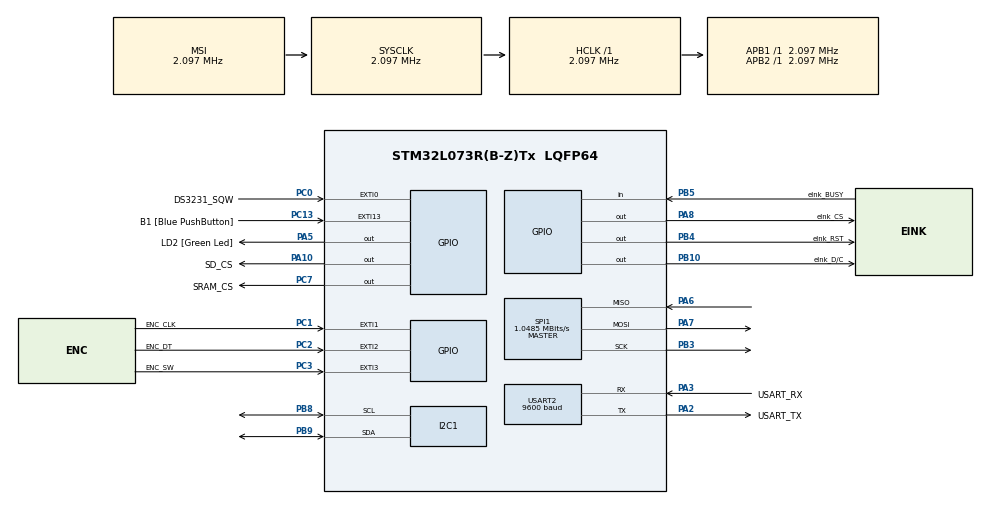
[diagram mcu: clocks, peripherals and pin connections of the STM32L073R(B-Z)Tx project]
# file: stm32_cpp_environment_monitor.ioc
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Dma.Request0=SPI1_TX
Dma.Request1=SPI1_RX
Dma.SPI1_RX.1.Direction=DMA_PERIPH_TO_MEMORY
Dma.SPI1_RX.1.Instance=DMA1_Channel2
Dma.SPI1_RX.1.MemDataAlignment=DMA_MDATAALIGN_BYTE
Dma.SPI1_RX.1.MemInc=DMA_MINC_ENABLE
Dma.SPI1_RX.1.Mode=DMA_NORMAL
Dma.SPI1_RX.1.PeriphDataAlignment=DMA_PDATAALIGN_BYTE
Dma.SPI1_RX.1.PeriphInc=DMA_PINC_DISABLE
Dma.SPI1_RX.1.Priority=DMA_PRIORITY_HIGH
Dma.SPI1_TX.0.Direction=DMA_MEMORY_TO_PERIPH
Dma.SPI1_TX.0.Instance=DMA1_Channel3
Dma.SPI1_TX.0.MemDataAlignment=DMA_MDATAALIGN_BYTE
Dma.SPI1_TX.0.MemInc=DMA_MINC_ENABLE
Dma.SPI1_TX.0.Mode=DMA_NORMAL
Dma.SPI1_TX.0.PeriphDataAlignment=DMA_PDATAALIGN_BYTE
Dma.SPI1_TX.0.PeriphInc=DMA_PINC_DISABLE
Dma.SPI1_TX.0.Priority=DMA_PRIORITY_HIGH
FATFS._USE_MKFS=0
I2C1.Timing=0x00503D58
Mcu.Family=STM32L0
Mcu.Name=STM32L073R(B-Z)Tx
Mcu.Package=LQFP64
NVIC.DMA1_Channel2_3_IRQn=true\:0\:0\:false\:false\:true\:false\:true\:true
NVIC.EXTI0_1_IRQn=true\:0\:0\:false\:false\:true\:true\:true\:true
NVIC.EXTI2_3_IRQn=true\:0\:0\:false\:false\:true\:true\:true\:true
PA10.GPIO_Label=SD_CS
PA10.PinState=GPIO_PIN_SET
PA10.Signal=GPIO_Output
PA13.GPIO_Label=TMS
PA13.Mode=Serial_Wire
PA13.Signal=SYS_SWDIO
PA14.GPIO_Label=TCK
PA14.Mode=Serial_Wire
PA14.Signal=SYS_SWCLK
PA2.GPIO_Label=USART_TX
PA2.Mode=Asynchronous
PA2.Signal=USART2_TX
PA3.GPIO_Label=USART_RX
PA3.Mode=Asynchronous
PA3.Signal=USART2_RX
PA5.GPIO_Label=LD2 [Green Led]
PA5.Signal=GPIO_Output
PA6.Mode=Full_Duplex_Master
PA6.Signal=SPI1_MISO
PA7.Mode=Full_Duplex_Master
PA7.Signal=SPI1_MOSI
PA8.GPIO_Label=eInk_CS
PA8.PinState=GPIO_PIN_SET
PA8.Signal=GPIO_Output
PB10.GPIO_Label=eInk_D/C
PB10.Signal=GPIO_Output
PB3.Mode=Full_Duplex_Master
PB3.Signal=SPI1_SCK
PB4.GPIO_Label=eInk_RST
PB4.PinState=GPIO_PIN_SET
PB4.Signal=GPIO_Output
PB5.GPIO_Label=eInk_BUSY
PB5.Signal=GPIO_Input
PB8.GPIO_FM8=I2C_FASTMODEPLUS_PB8
PB8.Mode=I2C
PB8.Signal=I2C1_SCL
PB9.GPIO_FM9=I2C_FASTMODEPLUS_PB9
PB9.Mode=I2C
PB9.Signal=I2C1_SDA
PC0.GPIO_Label=DS3231_SQW
PC0.GPIO_ModeDefaultEXTI=GPIO_MODE_IT_FALLING
PC0.GPIO_PuPd=GPIO_PULLUP
PC0.Signal=GPXTI0
PC1.GPIO_Label=ENC_CLK
PC1.GPIO_ModeDefaultEXTI=GPIO_MODE_IT_RISING_FALLING
PC1.GPIO_PuPd=GPIO_PULLUP
PC1.Signal=GPXTI1
PC13.GPIO_Label=B1 [Blue PushButton]
PC13.GPIO_ModeDefaultEXTI=GPIO_MODE_IT_FALLING
PC13.Signal=GPXTI13
PC14-OSC32_IN.Mode=LSE-External-Oscillator
PC14-OSC32_IN.Signal=RCC_OSC32_IN
PC15-OSC32_OUT.Mode=LSE-External-Oscillator
PC15-OSC32_OUT.Signal=RCC_OSC32_OUT
PC2.GPIO_Label=ENC_DT
PC2.GPIO_ModeDefaultEXTI=GPIO_MODE_IT_RISING_FALLING
PC2.GPIO_PuPd=GPIO_PULLUP
PC2.Signal=GPXTI2
PC3.GPIO_Label=ENC_SW
PC3.GPIO_ModeDefaultEXTI=GPIO_MODE_IT_FALLING
PC3.GPIO_PuPd=GPIO_PULLUP
PC3.Signal=GPXTI3
PC7.GPIO_Label=SRAM_CS
PC7.PinState=GPIO_PIN_SET
PC7.Signal=GPIO_Output
PH0-OSC_IN.GPIO_Label=MCO
PH0-OSC_IN.Signal=RCC_OSC_IN
ProjectManager.HeapSize=0x200
ProjectManager.StackSize=0x400
ProjectManager.TargetToolchain=CMake
RCC.AHBFreq_Value=2097000
RCC.APB1Freq_Value=2097000
RCC.APB1TimFreq_Value=2097000
RCC.APB2Freq_Value=2097000
RCC.APB2TimFreq_Value=2097000
RCC.HSE_VALUE=8000000
RCC.HSI16_VALUE=16000000
RCC.HSI48_VALUE=48000000
RCC.HSI_VALUE=16000000
RCC.I2c1ClockSelection=RCC_I2C1CLKSOURCE_HSI
RCC.MSI_VALUE=2097000
RCC.PWR_Regulator_Voltage_Scale=PWR_REGULATOR_VOLTAGE_SCALE3
RCC.SYSCLKFreq_VALUE=2097000
RCC.VCOOutputFreq_Value=48000000
SPI1.CalculateBaudRate=1.0485 MBits/s
SPI1.Direction=SPI_DIRECTION_2LINES
SPI1.Mode=SPI_MODE_MASTER
SPI1.VirtualType=VM_MASTER
USART2.BaudRate=9600
USART2.VirtualMode-Asynchronous=VM_ASYNC
VP_FATFS_VS_Generic.Mode=User_defined
board=NUCLEO-L073RZ

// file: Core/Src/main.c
/* USER CODE BEGIN Header */
/**
  ******************************************************************************
  * @file           : main.c
  * @brief          : Main program body
  ******************************************************************************
  * @attention
  *
  * Copyright (c) 2026 STMicroelectronics.
  * All rights reserved.
  *
  * This software is licensed under terms that can be found in the LICENSE file
  * in the root directory of this software component.
  * If no LICENSE file comes with this software, it is provided AS-IS.
  *
  ******************************************************************************
  */
/* USER CODE END Header */
#include "main.h"
#include "fatfs.h"

/* USER CODE BEGIN Includes */
#include "app.h"
/* USER CODE END Includes */

UART_HandleTypeDef huart2;

void SystemClock_Config(void);
static void MX_GPIO_Init(void);
static void MX_DMA_Init(void);
static void MX_SPI1_Init(void);
static void MX_USART2_UART_Init(void);
static void MX_I2C1_Init(void);

int main(void)
{

  /* MCU Configuration--------------------------------------------------------*/

  /* Reset of all peripherals, Initializes the Flash interface and the Systick. */
  HAL_Init();

  /* Configure the system clock */
  SystemClock_Config();

  /* Initialize all configured peripherals */
  MX_GPIO_Init();
  MX_DMA_Init();
  MX_SPI1_Init();
  MX_USART2_UART_Init();
  MX_I2C1_Init();
  MX_FATFS_Init();
  /* USER CODE BEGIN 2 */
  AppMain();
  /* USER CODE END 2 */

  /* Infinite loop */
  while (1)
  {

  }
}

void SystemClock_Config(void)
{
  RCC_OscInitTypeDef RCC_OscInitStruct = {0};
  RCC_ClkInitTypeDef RCC_ClkInitStruct = {0};
  RCC_PeriphCLKInitTypeDef PeriphClkInit = {0};

  /** Configure the main internal regulator output voltage
  */
  __HAL_PWR_VOLTAGESCALING_CONFIG(PWR_REGULATOR_VOLTAGE_SCALE3);

  /** Initializes the RCC Oscillators according to the specified parameters
  * in the RCC_OscInitTypeDef structure.
  */
  RCC_OscInitStruct.OscillatorType = RCC_OSCILLATORTYPE_HSI|RCC_OSCILLATORTYPE_MSI;
  RCC_OscInitStruct.HSIState = RCC_HSI_ON;
  RCC_OscInitStruct.HSICalibrationValue = RCC_HSICALIBRATION_DEFAULT;
  RCC_OscInitStruct.MSIState = RCC_MSI_ON;
  RCC_OscInitStruct.MSICalibrationValue = 0;
  RCC_OscInitStruct.MSIClockRange = RCC_MSIRANGE_5;
  RCC_OscInitStruct.PLL.PLLState = RCC_PLL_NONE;
  if (HAL_RCC_OscConfig(&RCC_OscInitStruct) != HAL_OK)
  {
    Error_Handler();
  }

  /** Initializes the CPU, AHB and APB buses clocks
  */
  RCC_ClkInitStruct.ClockType = RCC_CLOCKTYPE_HCLK|RCC_CLOCKTYPE_SYSCLK
                              |RCC_CLOCKTYPE_PCLK1|RCC_CLOCKTYPE_PCLK2;
  RCC_ClkInitStruct.SYSCLKSource = RCC_SYSCLKSOURCE_MSI;
  RCC_ClkInitStruct.AHBCLKDivider = RCC_SYSCLK_DIV1;
  RCC_ClkInitStruct.APB1CLKDivider = RCC_HCLK_DIV1;
  RCC_ClkInitStruct.APB2CLKDivider = RCC_HCLK_DIV1;

  if (HAL_RCC_ClockConfig(&RCC_ClkInitStruct, FLASH_LATENCY_0) != HAL_OK)
  {
    Error_Handler();
  }
  PeriphClkInit.PeriphClockSelection = RCC_PERIPHCLK_USART2|RCC_PERIPHCLK_I2C1;
  PeriphClkInit.Usart2ClockSelection = RCC_USART2CLKSOURCE_PCLK1;
  PeriphClkInit.I2c1ClockSelection = RCC_I2C1CLKSOURCE_HSI;
  if (HAL_RCCEx_PeriphCLKConfig(&PeriphClkInit) != HAL_OK)
  {
    Error_Handler();
  }
}

static void MX_I2C1_Init(void)
{

  LL_I2C_InitTypeDef I2C_InitStruct = {0};

  LL_GPIO_InitTypeDef GPIO_InitStruct = {0};

  LL_IOP_GRP1_EnableClock(LL_IOP_GRP1_PERIPH_GPIOB);
  /**I2C1 GPIO Configuration
  PB8   ------> I2C1_SCL
  PB9   ------> I2C1_SDA
  */
  GPIO_InitStruct.Pin = LL_GPIO_PIN_8;
  GPIO_InitStruct.Mode = LL_GPIO_MODE_ALTERNATE;
  GPIO_InitStruct.Speed = LL_GPIO_SPEED_FREQ_VERY_HIGH;
  GPIO_InitStruct.OutputType = LL_GPIO_OUTPUT_OPENDRAIN;
  GPIO_InitStruct.Pull = LL_GPIO_PULL_NO;
  GPIO_InitStruct.Alternate = LL_GPIO_AF_4;
  LL_GPIO_Init(GPIOB, &GPIO_InitStruct);

  GPIO_InitStruct.Pin = LL_GPIO_PIN_9;
  GPIO_InitStruct.Mode = LL_GPIO_MODE_ALTERNATE;
  GPIO_InitStruct.Speed = LL_GPIO_SPEED_FREQ_VERY_HIGH;
  GPIO_InitStruct.OutputType = LL_GPIO_OUTPUT_OPENDRAIN;
  GPIO_InitStruct.Pull = LL_GPIO_PULL_NO;
  GPIO_InitStruct.Alternate = LL_GPIO_AF_4;
  LL_GPIO_Init(GPIOB, &GPIO_InitStruct);

  LL_SYSCFG_EnableFastModePlus(LL_SYSCFG_I2C_FASTMODEPLUS_PB8);

  LL_SYSCFG_EnableFastModePlus(LL_SYSCFG_I2C_FASTMODEPLUS_PB9);

  /* Peripheral clock enable */
  LL_APB1_GRP1_EnableClock(LL_APB1_GRP1_PERIPH_I2C1);

  /** I2C Initialization
  */
  LL_I2C_EnableAutoEndMode(I2C1);
  LL_I2C_DisableOwnAddress2(I2C1);
  LL_I2C_DisableGeneralCall(I2C1);
  LL_I2C_EnableClockStretching(I2C1);
  I2C_InitStruct.PeripheralMode = LL_I2C_MODE_I2C;
  I2C_InitStruct.Timing = 0x00503D58;
  I2C_InitStruct.AnalogFilter = LL_I2C_ANALOGFILTER_ENABLE;
  I2C_InitStruct.DigitalFilter = 0;
  I2C_InitStruct.OwnAddress1 = 0;
  I2C_InitStruct.TypeAcknowledge = LL_I2C_ACK;
  I2C_InitStruct.OwnAddrSize = LL_I2C_OWNADDRESS1_7BIT;
  LL_I2C_Init(I2C1, &I2C_InitStruct);
  LL_I2C_SetOwnAddress2(I2C1, 0, LL_I2C_OWNADDRESS2_NOMASK);

}

static void MX_SPI1_Init(void)
{

  LL_SPI_InitTypeDef SPI_InitStruct = {0};

  LL_GPIO_InitTypeDef GPIO_InitStruct = {0};

  /* Peripheral clock enable */
  LL_APB2_GRP1_EnableClock(LL_APB2_GRP1_PERIPH_SPI1);

  LL_IOP_GRP1_EnableClock(LL_IOP_GRP1_PERIPH_GPIOA);
  LL_IOP_GRP1_EnableClock(LL_IOP_GRP1_PERIPH_GPIOB);
  /**SPI1 GPIO Configuration
  PA6   ------> SPI1_MISO
  PA7   ------> SPI1_MOSI
  PB3   ------> SPI1_SCK
  */
  GPIO_InitStruct.Pin = LL_GPIO_PIN_6;
  GPIO_InitStruct.Mode = LL_GPIO_MODE_ALTERNATE;
  GPIO_InitStruct.Speed = LL_GPIO_SPEED_FREQ_VERY_HIGH;
  GPIO_InitStruct.OutputType = LL_GPIO_OUTPUT_PUSHPULL;
  GPIO_InitStruct.Pull = LL_GPIO_PULL_NO;
  GPIO_InitStruct.Alternate = LL_GPIO_AF_0;
  LL_GPIO_Init(GPIOA, &GPIO_InitStruct);

  GPIO_InitStruct.Pin = LL_GPIO_PIN_7;
  GPIO_InitStruct.Mode = LL_GPIO_MODE_ALTERNATE;
  GPIO_InitStruct.Speed = LL_GPIO_SPEED_FREQ_VERY_HIGH;
  GPIO_InitStruct.OutputType = LL_GPIO_OUTPUT_PUSHPULL;
  GPIO_InitStruct.Pull = LL_GPIO_PULL_NO;
  GPIO_InitStruct.Alternate = LL_GPIO_AF_0;
  LL_GPIO_Init(GPIOA, &GPIO_InitStruct);

  GPIO_InitStruct.Pin = LL_GPIO_PIN_3;
  GPIO_InitStruct.Mode = LL_GPIO_MODE_ALTERNATE;
  GPIO_InitStruct.Speed = LL_GPIO_SPEED_FREQ_VERY_HIGH;
  GPIO_InitStruct.OutputType = LL_GPIO_OUTPUT_PUSHPULL;
  GPIO_InitStruct.Pull = LL_GPIO_PULL_NO;
  GPIO_InitStruct.Alternate = LL_GPIO_AF_0;
  LL_GPIO_Init(GPIOB, &GPIO_InitStruct);

  /* SPI1 DMA Init */

  /* SPI1_TX Init */
  LL_DMA_SetPeriphRequest(DMA1, LL_DMA_CHANNEL_3, LL_DMA_REQUEST_1);

  LL_DMA_SetDataTransferDirection(DMA1, LL_DMA_CHANNEL_3, LL_DMA_DIRECTION_MEMORY_TO_PERIPH);

  LL_DMA_SetChannelPriorityLevel(DMA1, LL_DMA_CHANNEL_3, LL_DMA_PRIORITY_HIGH);

  LL_DMA_SetMode(DMA1, LL_DMA_CHANNEL_3, LL_DMA_MODE_NORMAL);

  LL_DMA_SetPeriphIncMode(DMA1, LL_DMA_CHANNEL_3, LL_DMA_PERIPH_NOINCREMENT);

  LL_DMA_SetMemoryIncMode(DMA1, LL_DMA_CHANNEL_3, LL_DMA_MEMORY_INCREMENT);

  LL_DMA_SetPeriphSize(DMA1, LL_DMA_CHANNEL_3, LL_DMA_PDATAALIGN_BYTE);

  LL_DMA_SetMemorySize(DMA1, LL_DMA_CHANNEL_3, LL_DMA_MDATAALIGN_BYTE);

  /* SPI1_RX Init */
  LL_DMA_SetPeriphRequest(DMA1, LL_DMA_CHANNEL_2, LL_DMA_REQUEST_1);

  LL_DMA_SetDataTransferDirection(DMA1, LL_DMA_CHANNEL_2, LL_DMA_DIRECTION_PERIPH_TO_MEMORY);

  LL_DMA_SetChannelPriorityLevel(DMA1, LL_DMA_CHANNEL_2, LL_DMA_PRIORITY_HIGH);

  LL_DMA_SetMode(DMA1, LL_DMA_CHANNEL_2, LL_DMA_MODE_NORMAL);

  LL_DMA_SetPeriphIncMode(DMA1, LL_DMA_CHANNEL_2, LL_DMA_PERIPH_NOINCREMENT);

  LL_DMA_SetMemoryIncMode(DMA1, LL_DMA_CHANNEL_2, LL_DMA_MEMORY_INCREMENT);

  LL_DMA_SetPeriphSize(DMA1, LL_DMA_CHANNEL_2, LL_DMA_PDATAALIGN_BYTE);

  LL_DMA_SetMemorySize(DMA1, LL_DMA_CHANNEL_2, LL_DMA_MDATAALIGN_BYTE);

  /* SPI1 parameter configuration*/
  SPI_InitStruct.TransferDirection = LL_SPI_FULL_DUPLEX;
  SPI_InitStruct.Mode = LL_SPI_MODE_MASTER;
  SPI_InitStruct.DataWidth = LL_SPI_DATAWIDTH_8BIT;
  SPI_InitStruct.ClockPolarity = LL_SPI_POLARITY_LOW;
  SPI_InitStruct.ClockPhase = LL_SPI_PHASE_1EDGE;
  SPI_InitStruct.NSS = LL_SPI_NSS_SOFT;
  SPI_InitStruct.BaudRate = LL_SPI_BAUDRATEPRESCALER_DIV2;
  SPI_InitStruct.BitOrder = LL_SPI_MSB_FIRST;
  SPI_InitStruct.CRCCalculation = LL_SPI_CRCCALCULATION_DISABLE;
  SPI_InitStruct.CRCPoly = 7;
  LL_SPI_Init(SPI1, &SPI_InitStruct);
  LL_SPI_SetStandard(SPI1, LL_SPI_PROTOCOL_MOTOROLA);

}

static void MX_USART2_UART_Init(void)
{

  huart2.Instance = USART2;
  huart2.Init.BaudRate = 9600;
  huart2.Init.WordLength = UART_WORDLENGTH_8B;
  huart2.Init.StopBits = UART_STOPBITS_1;
  huart2.Init.Parity = UART_PARITY_NONE;
  huart2.Init.Mode = UART_MODE_TX_RX;
  huart2.Init.HwFlowCtl = UART_HWCONTROL_NONE;
  huart2.Init.OverSampling = UART_OVERSAMPLING_16;
  huart2.Init.OneBitSampling = UART_ONE_BIT_SAMPLE_DISABLE;
  huart2.AdvancedInit.AdvFeatureInit = UART_ADVFEATURE_NO_INIT;
  if (HAL_UART_Init(&huart2) != HAL_OK)
  {
    Error_Handler();
  }

}

static void MX_DMA_Init(void)
{

  /* DMA controller clock enable */
  __HAL_RCC_DMA1_CLK_ENABLE();

  /* DMA interrupt init */
  /* DMA1_Channel2_3_IRQn interrupt configuration */
  NVIC_SetPriority(DMA1_Channel2_3_IRQn, 0);
  NVIC_EnableIRQ(DMA1_Channel2_3_IRQn);

}

static void MX_GPIO_Init(void)
{
  GPIO_InitTypeDef GPIO_InitStruct = {0};

  /* GPIO Ports Clock Enable */
  __HAL_RCC_GPIOC_CLK_ENABLE();
  __HAL_RCC_GPIOH_CLK_ENABLE();
  __HAL_RCC_GPIOA_CLK_ENABLE();
  __HAL_RCC_GPIOB_CLK_ENABLE();
  __HAL_RCC_GPIOD_CLK_ENABLE();

  /*Configure GPIO pin Output Level */
  HAL_GPIO_WritePin(LD2_GPIO_Port, LD2_Pin, GPIO_PIN_RESET);

  /*Configure GPIO pin Output Level */
  HAL_GPIO_WritePin(eInk_D_C_GPIO_Port, eInk_D_C_Pin, GPIO_PIN_RESET);

  /*Configure GPIO pin Output Level */
  HAL_GPIO_WritePin(SRAM_CS_GPIO_Port, SRAM_CS_Pin, GPIO_PIN_SET);

  /*Configure GPIO pin Output Level */
  HAL_GPIO_WritePin(GPIOA, eInk_CS_Pin|SD_CS_Pin, GPIO_PIN_SET);

  /*Configure GPIO pin Output Level */
  HAL_GPIO_WritePin(eInk_RST_GPIO_Port, eInk_RST_Pin, GPIO_PIN_SET);

  /*Configure GPIO pin : B1_Pin */
  GPIO_InitStruct.Pin = B1_Pin;
  GPIO_InitStruct.Mode = GPIO_MODE_IT_FALLING;
  GPIO_InitStruct.Pull = GPIO_NOPULL;
  HAL_GPIO_Init(B1_GPIO_Port, &GPIO_InitStruct);

  /*Configure GPIO pin : PH1 */
  GPIO_InitStruct.Pin = GPIO_PIN_1;
  GPIO_InitStruct.Mode = GPIO_MODE_ANALOG;
  GPIO_InitStruct.Pull = GPIO_NOPULL;
  HAL_GPIO_Init(GPIOH, &GPIO_InitStruct);

  /*Configure GPIO pins : DS3231_SQW_Pin ENC_SW_Pin */
  GPIO_InitStruct.Pin = DS3231_SQW_Pin|ENC_SW_Pin;
  GPIO_InitStruct.Mode = GPIO_MODE_IT_FALLING;
  GPIO_InitStruct.Pull = GPIO_PULLUP;
  HAL_GPIO_Init(GPIOC, &GPIO_InitStruct);

  /*Configure GPIO pins : ENC_CLK_Pin ENC_DT_Pin */
  GPIO_InitStruct.Pin = ENC_CLK_Pin|ENC_DT_Pin;
  GPIO_InitStruct.Mode = GPIO_MODE_IT_RISING_FALLING;
  GPIO_InitStruct.Pull = GPIO_PULLUP;
  HAL_GPIO_Init(GPIOC, &GPIO_InitStruct);

  /*Configure GPIO pins : PA0 PA1 PA4 PA9
                           PA11 PA12 PA15 */
  GPIO_InitStruct.Pin = GPIO_PIN_0|GPIO_PIN_1|GPIO_PIN_4|GPIO_PIN_9
                          |GPIO_PIN_11|GPIO_PIN_12|GPIO_PIN_15;
  GPIO_InitStruct.Mode = GPIO_MODE_ANALOG;
  GPIO_InitStruct.Pull = GPIO_NOPULL;
  HAL_GPIO_Init(GPIOA, &GPIO_InitStruct);

  /*Configure GPIO pins : LD2_Pin eInk_CS_Pin SD_CS_Pin */
  GPIO_InitStruct.Pin = LD2_Pin|eInk_CS_Pin|SD_CS_Pin;
  GPIO_InitStruct.Mode = GPIO_MODE_OUTPUT_PP;
  GPIO_InitStruct.Pull = GPIO_NOPULL;
  GPIO_InitStruct.Speed = GPIO_SPEED_FREQ_LOW;
  HAL_GPIO_Init(GPIOA, &GPIO_InitStruct);

  /*Configure GPIO pins : PC4 PC5 PC6 PC8
                           PC9 PC10 PC11 PC12 */
  GPIO_InitStruct.Pin = GPIO_PIN_4|GPIO_PIN_5|GPIO_PIN_6|GPIO_PIN_8
                          |GPIO_PIN_9|GPIO_PIN_10|GPIO_PIN_11|GPIO_PIN_12;
  GPIO_InitStruct.Mode = GPIO_MODE_ANALOG;
  GPIO_InitStruct.Pull = GPIO_NOPULL;
  HAL_GPIO_Init(GPIOC, &GPIO_InitStruct);

  /*Configure GPIO pins : PB0 PB1 PB2 PB11
                           PB12 PB13 PB14 PB15
                           PB6 PB7 */
  GPIO_InitStruct.Pin = GPIO_PIN_0|GPIO_PIN_1|GPIO_PIN_2|GPIO_PIN_11
                          |GPIO_PIN_12|GPIO_PIN_13|GPIO_PIN_14|GPIO_PIN_15
                          |GPIO_PIN_6|GPIO_PIN_7;
  GPIO_InitStruct.Mode = GPIO_MODE_ANALOG;
  GPIO_InitStruct.Pull = GPIO_NOPULL;
  HAL_GPIO_Init(GPIOB, &GPIO_InitStruct);

  /*Configure GPIO pins : eInk_D_C_Pin eInk_RST_Pin */
  GPIO_InitStruct.Pin = eInk_D_C_Pin|eInk_RST_Pin;
  GPIO_InitStruct.Mode = GPIO_MODE_OUTPUT_PP;
  GPIO_InitStruct.Pull = GPIO_NOPULL;
  GPIO_InitStruct.Speed = GPIO_SPEED_FREQ_LOW;
  HAL_GPIO_Init(GPIOB, &GPIO_InitStruct);

  /*Configure GPIO pin : SRAM_CS_Pin */
  GPIO_InitStruct.Pin = SRAM_CS_Pin;
  GPIO_InitStruct.Mode = GPIO_MODE_OUTPUT_PP;
  GPIO_InitStruct.Pull = GPIO_NOPULL;
  GPIO_InitStruct.Speed = GPIO_SPEED_FREQ_LOW;
  HAL_GPIO_Init(SRAM_CS_GPIO_Port, &GPIO_InitStruct);

  /*Configure GPIO pin : PD2 */
  GPIO_InitStruct.Pin = GPIO_PIN_2;
  GPIO_InitStruct.Mode = GPIO_MODE_ANALOG;
  GPIO_InitStruct.Pull = GPIO_NOPULL;
  HAL_GPIO_Init(GPIOD, &GPIO_InitStruct);

  /*Configure GPIO pin : eInk_BUSY_Pin */
  GPIO_InitStruct.Pin = eInk_BUSY_Pin;
  GPIO_InitStruct.Mode = GPIO_MODE_INPUT;
  GPIO_InitStruct.Pull = GPIO_NOPULL;
  HAL_GPIO_Init(eInk_BUSY_GPIO_Port, &GPIO_InitStruct);

  /* EXTI interrupt init*/
  HAL_NVIC_SetPriority(EXTI0_1_IRQn, 0, 0);
  HAL_NVIC_EnableIRQ(EXTI0_1_IRQn);

  HAL_NVIC_SetPriority(EXTI2_3_IRQn, 0, 0);
  HAL_NVIC_EnableIRQ(EXTI2_3_IRQn);

}

void Error_Handler(void)
{
  __disable_irq();
  while (1)
  {
  }
}
